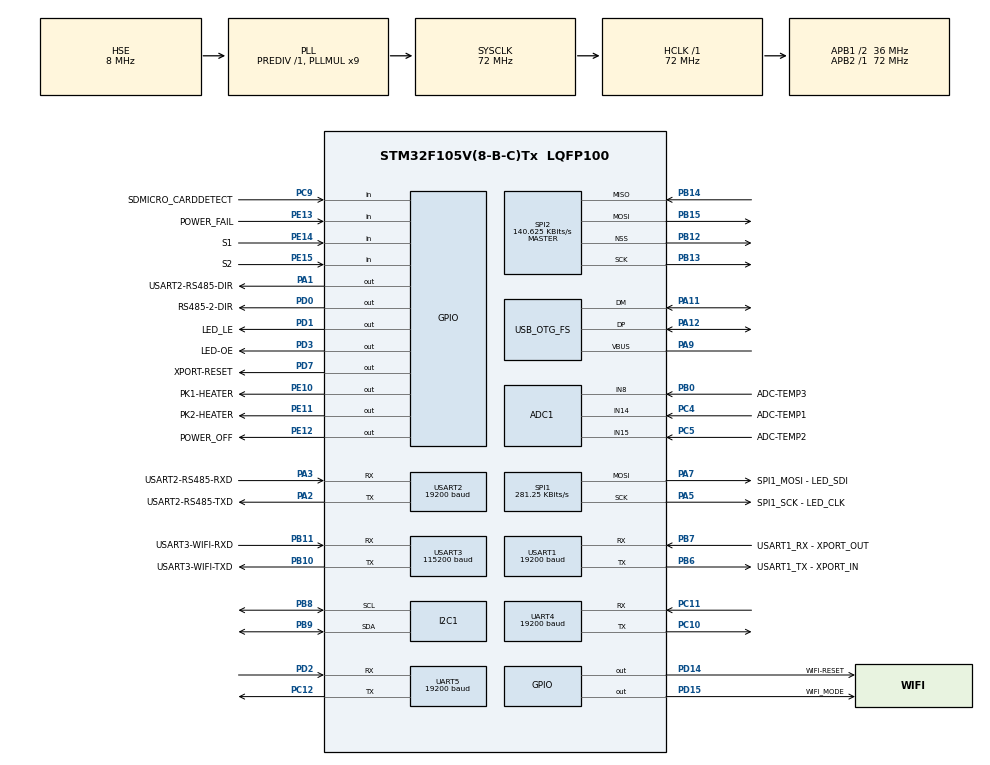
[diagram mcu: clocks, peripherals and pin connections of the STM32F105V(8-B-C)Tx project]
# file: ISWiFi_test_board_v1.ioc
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ADC1.Channel-4\#ChannelRegularConversion=ADC_CHANNEL_15
ADC1.ContinuousConvMode=DISABLE
ADC1.DataAlign=ADC_DATAALIGN_RIGHT
ADC1.DiscontinuousConvMode=DISABLE
ADC1.EnableAnalogWatchDog=false
ADC1.EnableRegularConversion=ENABLE
ADC1.ExternalTrigConv=ADC_SOFTWARE_START
ADC1.InjNumberOfConversion=0
ADC1.NbrOfConversion=1
ADC1.NbrOfConversionFlag=1
ADC1.Rank-4\#ChannelRegularConversion=1
ADC1.SamplingTime-4\#ChannelRegularConversion=ADC_SAMPLETIME_1CYCLE_5
ADC1.ScanConvMode=ADC_SCAN_DISABLE
ADC1.master=1
FREERTOS.Tasks01=defaultTask,0,128,StartDefaultTask,Default,NULL
Mcu.Family=STM32F1
Mcu.Name=STM32F105V(8-B-C)Tx
Mcu.Package=LQFP100
NVIC.OTG_FS_IRQn=true\:5\:0\:false\:false\:true\:true
NVIC.PriorityGroup=NVIC_PRIORITYGROUP_4
NVIC.UART4_IRQn=true\:5\:0\:false\:false\:true\:true
NVIC.UART5_IRQn=true\:5\:0\:false\:false\:true\:true
NVIC.USART1_IRQn=true\:5\:0\:false\:false\:true\:true
NVIC.USART2_IRQn=true\:5\:0\:false\:false\:true\:true
NVIC.USART3_IRQn=true\:5\:0\:false\:false\:true\:true
OSC_IN.Mode=HSE-External-Oscillator
OSC_IN.Signal=RCC_OSC_IN
OSC_OUT.Mode=HSE-External-Oscillator
OSC_OUT.Signal=RCC_OSC_OUT
PA1.GPIO_Label=USART2-RS485-DIR
PA1.Signal=GPIO_Output
PA11.Mode=Device_Only
PA11.Signal=USB_OTG_FS_DM
PA12.Mode=Device_Only
PA12.Signal=USB_OTG_FS_DP
PA13.Mode=JTAG_5_pins
PA13.Signal=SYS_JTMS-SWDIO
PA14.Mode=JTAG_5_pins
PA14.Signal=SYS_JTCK-SWCLK
PA15.Mode=JTAG_5_pins
PA15.Signal=SYS_JTDI
PA2.GPIO_Label=USART2-RS485-TXD
PA2.Mode=Asynchronous
PA2.Signal=USART2_TX
PA3.GPIO_Label=USART2-RS485-RXD
PA3.Mode=Asynchronous
PA3.Signal=USART2_RX
PA5.GPIO_Label=SPI1_SCK - LED_CLK
PA5.Mode=TX_Only_Simplex_Unidirect_Master
PA5.Signal=SPI1_SCK
PA7.GPIO_Label=SPI1_MOSI - LED_SDI
PA7.Mode=TX_Only_Simplex_Unidirect_Master
PA7.Signal=SPI1_MOSI
PA9.Mode=Activate_VBUS
PA9.Signal=USB_OTG_FS_VBUS
PB0.GPIO_Label=ADC-TEMP3
PB0.Signal=ADCx_IN8
PB10.GPIO_Label=USART3-WIFI-TXD
PB10.Mode=Asynchronous
PB10.Signal=USART3_TX
PB11.GPIO_Label=USART3-WIFI-RXD
PB11.Mode=Asynchronous
PB11.Signal=USART3_RX
PB12.Mode=NSS_Signal_Hard_Output
PB12.Signal=SPI2_NSS
PB13.Mode=Full_Duplex_Master
PB13.Signal=SPI2_SCK
PB14.Mode=Full_Duplex_Master
PB14.Signal=SPI2_MISO
PB15.Mode=Full_Duplex_Master
PB15.Signal=SPI2_MOSI
PB3.Mode=JTAG_5_pins
PB3.Signal=SYS_JTDO
PB4.Mode=JTAG_5_pins
PB4.Signal=SYS_NJTRST
PB6.GPIO_Label=USART1_TX - XPORT_IN
PB6.Mode=Asynchronous
PB6.Signal=USART1_TX
PB7.GPIO_Label=USART1_RX - XPORT_OUT
PB7.Mode=Asynchronous
PB7.Signal=USART1_RX
PB8.Mode=I2C
PB8.Signal=I2C1_SCL
PB9.Mode=I2C
PB9.Signal=I2C1_SDA
PC10.Mode=Asynchronous
PC10.Signal=UART4_TX
PC11.Mode=Asynchronous
PC11.Signal=UART4_RX
PC12.Mode=Asynchronous
PC12.Signal=UART5_TX
PC14-OSC32_IN.Mode=LSE-External-Oscillator
PC14-OSC32_IN.Signal=RCC_OSC32_IN
PC15-OSC32_OUT.Mode=LSE-External-Oscillator
PC15-OSC32_OUT.Signal=RCC_OSC32_OUT
PC4.GPIO_Label=ADC-TEMP1
PC4.Signal=ADCx_IN14
PC5.GPIO_Label=ADC-TEMP2
PC5.Signal=ADCx_IN15
PC9.GPIO_Label=SDMICRO_CARDDETECT
PC9.Signal=GPIO_Input
PD0.GPIO_Label=RS485-2-DIR
PD0.Signal=GPIO_Output
PD1.GPIO_Label=LED_LE
PD1.Signal=GPIO_Output
PD14.GPIO_Label=WIFI-RESET
PD14.Signal=GPIO_Output
PD15.GPIO_Label=WIFI_MODE
PD15.Signal=GPIO_Output
PD2.Mode=Asynchronous
PD2.Signal=UART5_RX
PD3.GPIO_Label=LED-OE
PD3.Signal=GPIO_Output
PD7.GPIO_Label=XPORT-RESET
PD7.Signal=GPIO_Output
PE10.GPIO_Label=PK1-HEATER
PE10.Signal=GPIO_Output
PE11.GPIO_Label=PK2-HEATER
PE11.Signal=GPIO_Output
PE12.GPIO_Label=POWER_OFF
PE12.Signal=GPIO_Output
PE13.GPIO_Label=POWER_FAIL
PE13.Signal=GPIO_Input
PE14.GPIO_Label=S1
PE14.Signal=GPIO_Input
PE15.GPIO_Label=S2
PE15.Signal=GPIO_Input
ProjectManager.HeapSize=0x200
ProjectManager.StackSize=0x400
ProjectManager.TargetToolchain=SW4STM32
RCC.ADCPresc=RCC_ADCPCLK2_DIV6
RCC.AHBFreq_Value=72000000
RCC.APB1CLKDivider=RCC_HCLK_DIV2
RCC.APB1Freq_Value=36000000
RCC.APB1TimFreq_Value=72000000
RCC.APB2Freq_Value=72000000
RCC.APB2TimFreq_Value=72000000
RCC.HCLKFreq_Value=72000000
RCC.PLLMUL=RCC_PLL_MUL9
RCC.SYSCLKFreq_VALUE=72000000
RCC.SYSCLKSource=RCC_SYSCLKSOURCE_PLLCLK
RCC.USBFreq_Value=48000000
RTC.Format=RTC_FORMAT_BIN
RTC.Month=RTC_MONTH_MAY
RTC.Year=17
SH.ADCx_IN14.0=ADC1_IN14,IN14
SH.ADCx_IN15.0=ADC1_IN15,IN15
SH.ADCx_IN8.0=ADC1_IN8,IN8
SPI1.BaudRatePrescaler=SPI_BAUDRATEPRESCALER_256
SPI1.CalculateBaudRate=281.25 KBits/s
SPI1.DataSize=SPI_DATASIZE_8BIT
SPI1.Direction=SPI_DIRECTION_2LINES
SPI1.Mode=SPI_MODE_MASTER
SPI1.VirtualType=VM_MASTER
SPI2.BaudRatePrescaler=SPI_BAUDRATEPRESCALER_256
SPI2.CalculateBaudRate=140.625 KBits/s
SPI2.Direction=SPI_DIRECTION_2LINES
SPI2.Mode=SPI_MODE_MASTER
SPI2.VirtualNSS=VM_NSSHARD
SPI2.VirtualType=VM_MASTER
UART4.BaudRate=19200
UART4.VirtualMode=Asynchronous
UART5.BaudRate=19200
UART5.VirtualMode=Asynchronous
USART1.BaudRate=19200
USART1.VirtualMode=VM_ASYNC
USART2.BaudRate=19200
USART2.VirtualMode=VM_ASYNC
USART3.BaudRate=115200
USART3.VirtualMode=VM_ASYNC
USB_DEVICE.CLASS_NAME_FS=CDC
USB_DEVICE.VirtualMode=Cdc
USB_DEVICE.VirtualModeFS=Cdc_FS
USB_OTG_FS.VirtualMode=Device_Only
VP_FREERTOS_VS_ENABLE.Mode=Enabled
VP_RTC_No_RTC_Output.Mode=RTC_OUT_NO
VP_RTC_VS_RTC_Activate.Mode=RTC_Enabled
VP_USB_DEVICE_VS_USB_DEVICE_CDC_FS.Mode=CDC_FS
board=ISWiFi_test_board_v1

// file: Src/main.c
/**
  ******************************************************************************
  * File Name          : main.c
  * Description        : Main program body
  ******************************************************************************
  *
  * Copyright (c) 2017 STMicroelectronics International N.V.
  * All rights reserved.
  *
  * Redistribution and use in source and binary forms, with or without
  * modification, are permitted, provided that the following conditions are met:
  *
  * 1. Redistribution of source code must retain the above copyright notice,
  *    this list of conditions and the following disclaimer.
  * 2. Redistributions in binary form must reproduce the above copyright notice,
  *    this list of conditions and the following disclaimer in the documentation
  *    and/or other materials provided with the distribution.
  * 3. Neither the name of STMicroelectronics nor the names of other
  *    contributors to this software may be used to endorse or promote products
  *    derived from this software without specific written permission.
  * 4. This software, including modifications and/or derivative works of this
  *    software, must execute solely and exclusively on microcontroller or
  *    microprocessor devices manufactured by or for STMicroelectronics.
  * 5. Redistribution and use of this software other than as permitted under
  *    this license is void and will automatically terminate your rights under
  *    this license.
  *
  * THIS SOFTWARE IS PROVIDED BY STMICROELECTRONICS AND CONTRIBUTORS "AS IS"
  * AND ANY EXPRESS, IMPLIED OR STATUTORY WARRANTIES, INCLUDING, BUT NOT
  * LIMITED TO, THE IMPLIED WARRANTIES OF MERCHANTABILITY, FITNESS FOR A
  * PARTICULAR PURPOSE AND NON-INFRINGEMENT OF THIRD PARTY INTELLECTUAL PROPERTY
  * RIGHTS ARE DISCLAIMED TO THE FULLEST EXTENT PERMITTED BY LAW. IN NO EVENT
  * SHALL STMICROELECTRONICS OR CONTRIBUTORS BE LIABLE FOR ANY DIRECT, INDIRECT,
  * INCIDENTAL, SPECIAL, EXEMPLARY, OR CONSEQUENTIAL DAMAGES (INCLUDING, BUT NOT
  * LIMITED TO, PROCUREMENT OF SUBSTITUTE GOODS OR SERVICES; LOSS OF USE, DATA,
  * OR PROFITS; OR BUSINESS INTERRUPTION) HOWEVER CAUSED AND ON ANY THEORY OF
  * LIABILITY, WHETHER IN CONTRACT, STRICT LIABILITY, OR TORT (INCLUDING
  * NEGLIGENCE OR OTHERWISE) ARISING IN ANY WAY OUT OF THE USE OF THIS SOFTWARE,
  * EVEN IF ADVISED OF THE POSSIBILITY OF SUCH DAMAGE.
  *
  ******************************************************************************
  */
#include "main.h"
#include "stm32f1xx_hal.h"
#include "cmsis_os.h"
#include "usb_device.h"

#include "common.h"
#include "app.h"
#include "vcp.h"
#include "led.h"
#include "relays.h"
#include "ADC.h"
#include "HysteresisController.h"
//#include "database.h"

ADC_HandleTypeDef hadc1;

I2C_HandleTypeDef hi2c1;

RTC_HandleTypeDef hrtc;

SPI_HandleTypeDef hspi1;
SPI_HandleTypeDef hspi2;

UART_HandleTypeDef huart4;
UART_HandleTypeDef huart5;
UART_HandleTypeDef huart1;
UART_HandleTypeDef huart2;
UART_HandleTypeDef huart3;

osThreadId defaultTaskHandle;

/* USER CODE BEGIN PV */
/* Private variables ---------------------------------------------------------*/

/* USER CODE END PV */

void SystemClock_Config(void);
void Error_Handler(void);
static void MX_GPIO_Init(void);
static void MX_ADC1_Init(void);
static void MX_I2C1_Init(void);
static void MX_RTC_Init(void);
static void MX_SPI1_Init(void);
static void MX_SPI2_Init(void);
static void MX_UART4_Init(void);
static void MX_UART5_Init(void);
static void MX_USART1_UART_Init(void);
static void MX_USART2_UART_Init(void);
static void MX_USART3_UART_Init(void);
void StartDefaultTask(void const * argument);
void selfTest(void);

/* USER CODE END 0 */

int main(void)
{

  /* MCU Configuration----------------------------------------------------------*/

  /* Reset of all peripherals, Initializes the Flash interface and the Systick. */
  HAL_Init();

  /* Configure the system clock */
  SystemClock_Config();

  /* Initialize all configured peripherals */
  MX_GPIO_Init();
  MX_ADC1_Init();
  MX_I2C1_Init();
  MX_RTC_Init();
  MX_SPI1_Init();
  MX_SPI2_Init();
  MX_UART4_Init();
  MX_UART5_Init();
  MX_USART1_UART_Init();
  MX_USART2_UART_Init();
  MX_USART3_UART_Init();

  MX_USB_DEVICE_Init();

  /* USER CODE BEGIN 2 */

  LedInit();
  RelaysInit();

  //LedDown(OUT2);
  //selfTest();
    //selfTest();
  /* USER CODE END 2 */

  /* Create the thread(s) */
  /* definition and creation of defaultTask */

  //osThreadDef(DatabaseTask, DatabaseTask, osPriorityNormal, 0, 128);
  //osThreadCreate(osThread(DatabaseTask), &hadc1);
//
  //osThreadDef(defaultTask, StartDefaultTask, osPriorityNormal, 0, 512);
  //defaultTaskHandle = osThreadCreate(osThread(defaultTask), NULL);
  //osThreadDef(VcpTask, VcpTask, osPriorityNormal, 0, 128);
  //osThreadCreate(osThread(VcpTask), NULL);
  //sprintf(buf, "VCP Task Launched\r\n");
  //Send(buf, strlen(buf), 500);

  osThreadDef(ADCTask, ADCTask, osPriorityNormal, 0, 128);
  osThreadCreate(osThread(ADCTask), &hadc1);

  //sprintf(buf, "ADCTask Launched\r\n");
  //Send(buf, strlen(buf), 500);

  osThreadDef(TempControllerTask, TempControllerTask, osPriorityNormal, 0, 128);
  osThreadCreate(osThread(TempControllerTask), NULL);

  //sprintf(buf, "Controller Task Launched\r\n");
  //Send(buf, strlen(buf), 500);

  /* Start scheduler */
  osKernelStart();

  /* We should never get here as control is now taken by the scheduler */

  /* Infinite loop */
  while (1)
  {

  }

}

/** System Clock Configuration
*/
void SystemClock_Config(void)
{

  RCC_OscInitTypeDef RCC_OscInitStruct;
  RCC_ClkInitTypeDef RCC_ClkInitStruct;
  RCC_PeriphCLKInitTypeDef PeriphClkInit;

    /**Initializes the CPU, AHB and APB busses clocks
    */
  RCC_OscInitStruct.OscillatorType = RCC_OSCILLATORTYPE_LSI|RCC_OSCILLATORTYPE_HSE;
  RCC_OscInitStruct.HSEState = RCC_HSE_ON;
  RCC_OscInitStruct.HSEPredivValue = RCC_HSE_PREDIV_DIV1;
  RCC_OscInitStruct.HSIState = RCC_HSI_ON;
  RCC_OscInitStruct.LSIState = RCC_LSI_ON;
  RCC_OscInitStruct.Prediv1Source = RCC_PREDIV1_SOURCE_HSE;
  RCC_OscInitStruct.PLL.PLLState = RCC_PLL_ON;
  RCC_OscInitStruct.PLL.PLLSource = RCC_PLLSOURCE_HSE;
  RCC_OscInitStruct.PLL.PLLMUL = RCC_PLL_MUL9;
  RCC_OscInitStruct.PLL2.PLL2State = RCC_PLL_NONE;
  if (HAL_RCC_OscConfig(&RCC_OscInitStruct) != HAL_OK)
  {
    Error_Handler();
  }

    /**Initializes the CPU, AHB and APB busses clocks
    */
  RCC_ClkInitStruct.ClockType = RCC_CLOCKTYPE_HCLK|RCC_CLOCKTYPE_SYSCLK
                              |RCC_CLOCKTYPE_PCLK1|RCC_CLOCKTYPE_PCLK2;
  RCC_ClkInitStruct.SYSCLKSource = RCC_SYSCLKSOURCE_PLLCLK;
  RCC_ClkInitStruct.AHBCLKDivider = RCC_SYSCLK_DIV1;
  RCC_ClkInitStruct.APB1CLKDivider = RCC_HCLK_DIV2;
  RCC_ClkInitStruct.APB2CLKDivider = RCC_HCLK_DIV1;

  if (HAL_RCC_ClockConfig(&RCC_ClkInitStruct, FLASH_LATENCY_2) != HAL_OK)
  {
    Error_Handler();
  }

  PeriphClkInit.PeriphClockSelection = RCC_PERIPHCLK_RTC|RCC_PERIPHCLK_ADC
                              |RCC_PERIPHCLK_USB;
  PeriphClkInit.RTCClockSelection = RCC_RTCCLKSOURCE_LSI;
  PeriphClkInit.AdcClockSelection = RCC_ADCPCLK2_DIV6;
  PeriphClkInit.UsbClockSelection = RCC_USBCLKSOURCE_PLL_DIV3;
  if (HAL_RCCEx_PeriphCLKConfig(&PeriphClkInit) != HAL_OK)
  {
    Error_Handler();
  }

    /**Configure the Systick interrupt time
    */
  HAL_SYSTICK_Config(HAL_RCC_GetHCLKFreq()/1000);

    /**Configure the Systick
    */
  HAL_SYSTICK_CLKSourceConfig(SYSTICK_CLKSOURCE_HCLK);

    /**Configure the Systick interrupt time
    */
  __HAL_RCC_PLLI2S_ENABLE();

  /* SysTick_IRQn interrupt configuration */
  HAL_NVIC_SetPriority(SysTick_IRQn, 15, 0);
}

/* ADC1 init function */
static void MX_ADC1_Init(void)
{

  ADC_ChannelConfTypeDef sConfig;

    /**Common config
    */
  hadc1.Instance = ADC1;
  hadc1.Init.ScanConvMode = ADC_SCAN_DISABLE;
  hadc1.Init.ContinuousConvMode = DISABLE;
  hadc1.Init.DiscontinuousConvMode = DISABLE;
  hadc1.Init.ExternalTrigConv = ADC_SOFTWARE_START;
  hadc1.Init.DataAlign = ADC_DATAALIGN_RIGHT;
  hadc1.Init.NbrOfConversion = 1;
  if (HAL_ADC_Init(&hadc1) != HAL_OK)
  {
    Error_Handler();
  }

    /**Configure Regular Channel
    */
  sConfig.Channel = ADC_CHANNEL_15;
  sConfig.Rank = 1;
  sConfig.SamplingTime = ADC_SAMPLETIME_1CYCLE_5;
  if (HAL_ADC_ConfigChannel(&hadc1, &sConfig) != HAL_OK)
  {
    Error_Handler();
  }

}

/* I2C1 init function */
static void MX_I2C1_Init(void)
{

  hi2c1.Instance = I2C1;
  hi2c1.Init.ClockSpeed = 100000;
  hi2c1.Init.DutyCycle = I2C_DUTYCYCLE_2;
  hi2c1.Init.OwnAddress1 = 0;
  hi2c1.Init.AddressingMode = I2C_ADDRESSINGMODE_7BIT;
  hi2c1.Init.DualAddressMode = I2C_DUALADDRESS_DISABLE;
  hi2c1.Init.OwnAddress2 = 0;
  hi2c1.Init.GeneralCallMode = I2C_GENERALCALL_DISABLE;
  hi2c1.Init.NoStretchMode = I2C_NOSTRETCH_DISABLE;
  if (HAL_I2C_Init(&hi2c1) != HAL_OK)
  {
    Error_Handler();
  }

}

/* RTC init function */
static void MX_RTC_Init(void)
{

  RTC_TimeTypeDef sTime;
  RTC_DateTypeDef DateToUpdate;

    /**Initialize RTC Only
    */
  hrtc.Instance = RTC;
  hrtc.Init.AsynchPrediv = RTC_AUTO_1_SECOND;
  hrtc.Init.OutPut = RTC_OUTPUTSOURCE_NONE;
  if (HAL_RTC_Init(&hrtc) != HAL_OK)
  {
    Error_Handler();
  }

    /**Initialize RTC and set the Time and Date
    */
  if(HAL_RTCEx_BKUPRead(&hrtc, RTC_BKP_DR1) != 0x32F2){
  sTime.Hours = 1;
  sTime.Minutes = 0;
  sTime.Seconds = 0;

  if (HAL_RTC_SetTime(&hrtc, &sTime, RTC_FORMAT_BIN) != HAL_OK)
  {
    Error_Handler();
  }

  DateToUpdate.WeekDay = RTC_WEEKDAY_MONDAY;
  DateToUpdate.Month = RTC_MONTH_MAY;
  DateToUpdate.Date = 1;
  DateToUpdate.Year = 17;

  if (HAL_RTC_SetDate(&hrtc, &DateToUpdate, RTC_FORMAT_BIN) != HAL_OK)
  {
    Error_Handler();
  }

    HAL_RTCEx_BKUPWrite(&hrtc,RTC_BKP_DR1,0x32F2);
  }

}

/* SPI1 init function */
static void MX_SPI1_Init(void)
{

  hspi1.Instance = SPI1;
  hspi1.Init.Mode = SPI_MODE_MASTER;
  hspi1.Init.Direction = SPI_DIRECTION_2LINES;
  hspi1.Init.DataSize = SPI_DATASIZE_8BIT;
  hspi1.Init.CLKPolarity = SPI_POLARITY_LOW;
  hspi1.Init.CLKPhase = SPI_PHASE_1EDGE;
  hspi1.Init.NSS = SPI_NSS_SOFT;
  hspi1.Init.BaudRatePrescaler = SPI_BAUDRATEPRESCALER_256;
  hspi1.Init.FirstBit = SPI_FIRSTBIT_MSB;
  hspi1.Init.TIMode = SPI_TIMODE_DISABLE;
  hspi1.Init.CRCCalculation = SPI_CRCCALCULATION_DISABLE;
  hspi1.Init.CRCPolynomial = 10;
  if (HAL_SPI_Init(&hspi1) != HAL_OK)
  {
    Error_Handler();
  }

}

/* SPI2 init function */
static void MX_SPI2_Init(void)
{

  hspi2.Instance = SPI2;
  hspi2.Init.Mode = SPI_MODE_MASTER;
  hspi2.Init.Direction = SPI_DIRECTION_2LINES;
  hspi2.Init.DataSize = SPI_DATASIZE_8BIT;
  hspi2.Init.CLKPolarity = SPI_POLARITY_LOW;
  hspi2.Init.CLKPhase = SPI_PHASE_1EDGE;
  hspi2.Init.NSS = SPI_NSS_HARD_OUTPUT;
  hspi2.Init.BaudRatePrescaler = SPI_BAUDRATEPRESCALER_256;
  hspi2.Init.FirstBit = SPI_FIRSTBIT_MSB;
  hspi2.Init.TIMode = SPI_TIMODE_DISABLE;
  hspi2.Init.CRCCalculation = SPI_CRCCALCULATION_DISABLE;
  hspi2.Init.CRCPolynomial = 10;
  if (HAL_SPI_Init(&hspi2) != HAL_OK)
  {
    Error_Handler();
  }

}

/* UART4 init function */
static void MX_UART4_Init(void)
{

  huart4.Instance = UART4;
  huart4.Init.BaudRate = 19200;
  huart4.Init.WordLength = UART_WORDLENGTH_8B;
  huart4.Init.StopBits = UART_STOPBITS_1;
  huart4.Init.Parity = UART_PARITY_NONE;
  huart4.Init.Mode = UART_MODE_TX_RX;
  huart4.Init.HwFlowCtl = UART_HWCONTROL_NONE;
  huart4.Init.OverSampling = UART_OVERSAMPLING_16;
  if (HAL_UART_Init(&huart4) != HAL_OK)
  {
    Error_Handler();
  }

}

/* UART5 init function */
static void MX_UART5_Init(void)
{

  huart5.Instance = UART5;
  huart5.Init.BaudRate = 19200;
  huart5.Init.WordLength = UART_WORDLENGTH_8B;
  huart5.Init.StopBits = UART_STOPBITS_1;
  huart5.Init.Parity = UART_PARITY_NONE;
  huart5.Init.Mode = UART_MODE_TX_RX;
  huart5.Init.HwFlowCtl = UART_HWCONTROL_NONE;
  huart5.Init.OverSampling = UART_OVERSAMPLING_16;
  if (HAL_UART_Init(&huart5) != HAL_OK)
  {
    Error_Handler();
  }

}

/* USART1 init function */
static void MX_USART1_UART_Init(void)
{

  huart1.Instance = USART1;
  huart1.Init.BaudRate = 19200;
  huart1.Init.WordLength = UART_WORDLENGTH_8B;
  huart1.Init.StopBits = UART_STOPBITS_1;
  huart1.Init.Parity = UART_PARITY_NONE;
  huart1.Init.Mode = UART_MODE_TX_RX;
  huart1.Init.HwFlowCtl = UART_HWCONTROL_NONE;
  huart1.Init.OverSampling = UART_OVERSAMPLING_16;
  if (HAL_UART_Init(&huart1) != HAL_OK)
  {
    Error_Handler();
  }

}

/* USART2 init function */
static void MX_USART2_UART_Init(void)
{

  huart2.Instance = USART2;
  huart2.Init.BaudRate = 19200;
  huart2.Init.WordLength = UART_WORDLENGTH_8B;
  huart2.Init.StopBits = UART_STOPBITS_1;
  huart2.Init.Parity = UART_PARITY_NONE;
  huart2.Init.Mode = UART_MODE_TX_RX;
  huart2.Init.HwFlowCtl = UART_HWCONTROL_NONE;
  huart2.Init.OverSampling = UART_OVERSAMPLING_16;
  if (HAL_UART_Init(&huart2) != HAL_OK)
  {
    Error_Handler();
  }

}

/* USART3 init function */
static void MX_USART3_UART_Init(void)
{

  huart3.Instance = USART3;
  huart3.Init.BaudRate = 115200;
  huart3.Init.WordLength = UART_WORDLENGTH_8B;
  huart3.Init.StopBits = UART_STOPBITS_1;
  huart3.Init.Parity = UART_PARITY_NONE;
  huart3.Init.Mode = UART_MODE_TX_RX;
  huart3.Init.HwFlowCtl = UART_HWCONTROL_NONE;
  huart3.Init.OverSampling = UART_OVERSAMPLING_16;
  if (HAL_UART_Init(&huart3) != HAL_OK)
  {
    Error_Handler();
  }

}

/** Configure pins as
        * Analog
        * Input
        * Output
        * EVENT_OUT
        * EXTI
*/
static void MX_GPIO_Init(void)
{

  GPIO_InitTypeDef GPIO_InitStruct;

  /* GPIO Ports Clock Enable */
  __HAL_RCC_GPIOC_CLK_ENABLE();
  __HAL_RCC_GPIOA_CLK_ENABLE();
  __HAL_RCC_GPIOB_CLK_ENABLE();
  __HAL_RCC_GPIOE_CLK_ENABLE();
  __HAL_RCC_GPIOD_CLK_ENABLE();

  /*Configure GPIO pin Output Level */
  HAL_GPIO_WritePin(USART2_RS485_DIR_GPIO_Port, USART2_RS485_DIR_Pin, GPIO_PIN_RESET);

  /*Configure GPIO pin Output Level */
  HAL_GPIO_WritePin(GPIOE, PK1_HEATER_Pin|PK2_HEATER_Pin|POWER_OFF_Pin, GPIO_PIN_RESET);

  /*Configure GPIO pin Output Level */
  HAL_GPIO_WritePin(GPIOD, WIFI_RESET_Pin|WIFI_MODE_Pin|RS485_2_DIR_Pin|LED_LE_Pin
                          |LED_OE_Pin|XPORT_RESET_Pin, GPIO_PIN_RESET);

  /*Configure GPIO pin : USART2_RS485_DIR_Pin */
  GPIO_InitStruct.Pin = USART2_RS485_DIR_Pin;
  GPIO_InitStruct.Mode = GPIO_MODE_OUTPUT_PP;
  GPIO_InitStruct.Speed = GPIO_SPEED_FREQ_LOW;
  HAL_GPIO_Init(USART2_RS485_DIR_GPIO_Port, &GPIO_InitStruct);

  /*Configure GPIO pins : PK1_HEATER_Pin PK2_HEATER_Pin POWER_OFF_Pin */
  GPIO_InitStruct.Pin = PK1_HEATER_Pin|PK2_HEATER_Pin|POWER_OFF_Pin;
  GPIO_InitStruct.Mode = GPIO_MODE_OUTPUT_PP;
  GPIO_InitStruct.Speed = GPIO_SPEED_FREQ_LOW;
  HAL_GPIO_Init(GPIOE, &GPIO_InitStruct);

  /*Configure GPIO pins : POWER_FAIL_Pin S1_Pin S2_Pin */
  GPIO_InitStruct.Pin = POWER_FAIL_Pin|S1_Pin|S2_Pin;
  GPIO_InitStruct.Mode = GPIO_MODE_INPUT;
  GPIO_InitStruct.Pull = GPIO_NOPULL;
  HAL_GPIO_Init(GPIOE, &GPIO_InitStruct);

  /*Configure GPIO pins : WIFI_RESET_Pin WIFI_MODE_Pin RS485_2_DIR_Pin LED_LE_Pin
                           LED_OE_Pin XPORT_RESET_Pin */
  GPIO_InitStruct.Pin = WIFI_RESET_Pin|WIFI_MODE_Pin|RS485_2_DIR_Pin|LED_LE_Pin
                          |LED_OE_Pin|XPORT_RESET_Pin;
  GPIO_InitStruct.Mode = GPIO_MODE_OUTPUT_PP;
  GPIO_InitStruct.Speed = GPIO_SPEED_FREQ_LOW;
  HAL_GPIO_Init(GPIOD, &GPIO_InitStruct);

  /*Configure GPIO pin : SDMICRO_CARDDETECT_Pin */
  GPIO_InitStruct.Pin = SDMICRO_CARDDETECT_Pin;
  GPIO_InitStruct.Mode = GPIO_MODE_INPUT;
  GPIO_InitStruct.Pull = GPIO_NOPULL;
  HAL_GPIO_Init(SDMICRO_CARDDETECT_GPIO_Port, &GPIO_InitStruct);

}

/* StartDefaultTask function */
void StartDefaultTask(void const * argument)
{

  /* init code for USB_DEVICE */

 //selfTest();
  /* USER CODE BEGIN 5 */
  /* Infinite loop */
  osDelay(5000);
  char buf[32];
  sprintf(buf, "Default Task Started:\r\n");
  Send(buf, strlen(buf), 500);

  for(;;)
  {
    osDelay(1000);

    //HAL_GPIO_TogglePin(GPIOE, PK1_HEATER_Pin);
  }
  /* USER CODE END 5 */
}

void Error_Handler(void)
{
  while(1)
  {
  }
}

/************************ (C) COPYRIGHT STMicroelectronics *****END OF FILE****/
